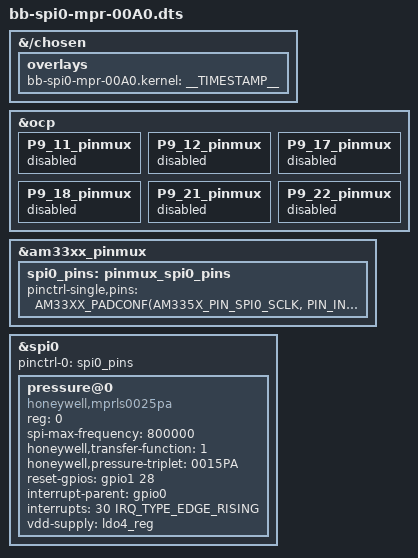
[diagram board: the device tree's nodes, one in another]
// SPDX-License-Identifier: GPL-2.0-only

/dts-v1/;
/plugin/;

#include <dt-bindings/gpio/gpio.h>
#include <dt-bindings/interrupt-controller/irq.h>
#include <dt-bindings/pinctrl/am33xx.h>

/*
 * Helper to show loaded overlays under: /proc/device-tree/chosen/overlays/
 */
&{/chosen} {
	overlays {
		bb-spi0-mpr-00A0.kernel = __TIMESTAMP__;
	};
};

/*
 * Free up the pins used by the cape from the pinmux helpers.
 */
&ocp {
	P9_11_pinmux { status = "disabled"; };	/* P9_11 end of conversion irq */
	P9_12_pinmux { status = "disabled"; };	/* P9_12 reset */
	P9_17_pinmux { status = "disabled"; };	/* P9_17 (A16) spi0_cs0.spi0_cs0 */
	P9_18_pinmux { status = "disabled"; };	/* P9_18 (B16) spi0_d1.spi0_d1 */
	P9_21_pinmux { status = "disabled"; };	/* P9_21 (B17) spi0_d0.spi0_d0 */
	P9_22_pinmux { status = "disabled"; };	/* P9_22 (A17) spi0_sclk.spi0_sclk */
};

&am33xx_pinmux {
	spi0_pins: pinmux_spi0_pins {
		pinctrl-single,pins = <
			AM33XX_PADCONF(AM335X_PIN_SPI0_SCLK, PIN_INPUT, MUX_MODE0)	/* P9_22 (A17) spi0_sclk.spi0_sclk */
			AM33XX_PADCONF(AM335X_PIN_SPI0_D0, PIN_INPUT, MUX_MODE0)	/* P9_21 (B17) spi0_d0.spi0_d0 */
			AM33XX_PADCONF(AM335X_PIN_SPI0_D1, PIN_INPUT, MUX_MODE0)	/* P9_18 (B16) spi0_d0.spi0_d1 */
			AM33XX_PADCONF(AM335X_PIN_SPI0_CS0, PIN_INPUT, MUX_MODE0)	/* P9_17 (A16) spi0_cs0.spi0_cs0 */
			AM33XX_PADCONF(AM335X_PIN_GPMC_WAIT0, PIN_INPUT, MUX_MODE7)	/* P9_11 (T17) EOC */
			AM33XX_PADCONF(AM335X_PIN_GPMC_BEN1, PIN_OUTPUT, MUX_MODE7)	/* P9_12 (U18) reset */
		>;
	};
};

&spi0 {
	#address-cells = <1>;
	#size-cells = <0>;

	status = "okay";
	pinctrl-names = "default";
	pinctrl-0 = <&spi0_pins>;

	pressure@0{
		compatible = "honeywell,mprls0025pa";
		reg = <0>;
		spi-max-frequency = <800000>;

		honeywell,transfer-function = <1>;
		honeywell,pressure-triplet = "0015PA";
		reset-gpios = <&gpio1 28 GPIO_ACTIVE_HIGH>;
		interrupt-parent = <&gpio0>;
		interrupts = <30 IRQ_TYPE_EDGE_RISING>;

		// in case of a custom range, unset pressure-triplet
		// and populate pmin-pascal and pmax-pascal
		// with the range limits converted into pascals
		//honeywell,pmin-pascal = <0>;
		//honeywell,pmax-pascal = <206850>;

		vdd-supply = <&ldo4_reg>;
		status = "okay";
	};
};
